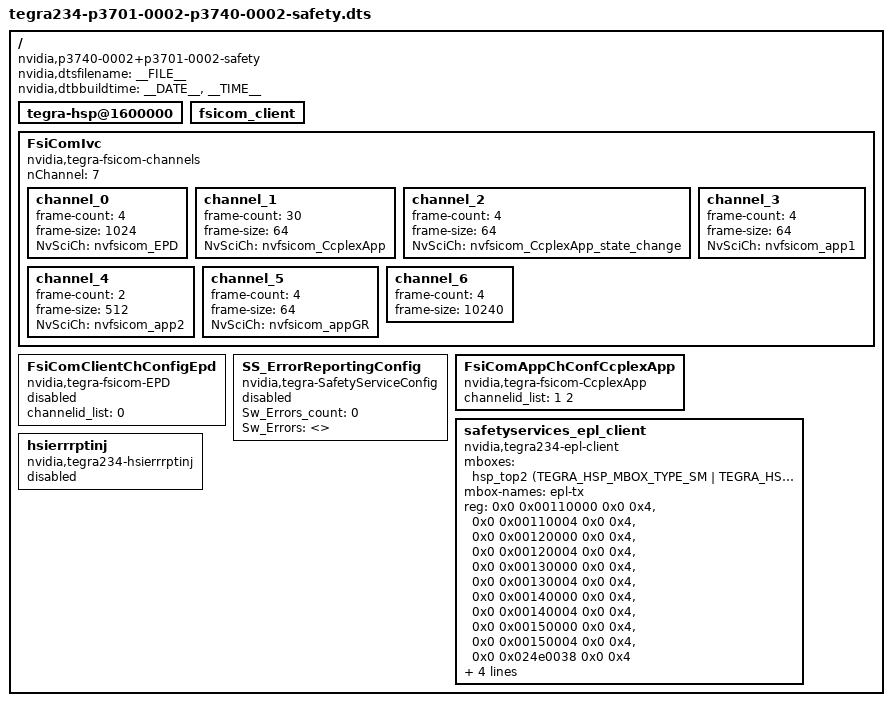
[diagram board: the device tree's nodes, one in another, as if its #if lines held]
/*
 * Top level DTS file for CVM:P3701-0002 and CVB:P3704-0002.
 *
 * Copyright (c) 2022, NVIDIA CORPORATION.  All rights reserved.
 *
 * This program is free software; you can redistribute it and/or modify
 * it under the terms of the GNU General Public License as published by
 * the Free Software Foundation; version 2 of the License.
 *
 * This program is distributed in the hope that it will be useful, but WITHOUT
 * ANY WARRANTY; without even the implied warranty of MERCHANTABILITY or
 * FITNESS FOR A PARTICULAR PURPOSE.  See the GNU General Public License for
 * more details.
 */

/dts-v1/;
#include "tegra234-p3701-0002-p3740-0002.dts"

/ {
	nvidia,dtsfilename = __FILE__;
	nvidia,dtbbuildtime = __DATE__, __TIME__;

	compatible = "nvidia,p3740-0002+p3701-0002-safety", "nvidia,tegra23x",
		      "nvidia,tegra234";

	/* This is hsp_top2 where fsi-ccplex comm happens in all below nodes */
	tegra-hsp@1600000 {
		status = "okay";
	};

	fsicom_client { /* Kernel driver on which FsiComIvc relies on */
		status = "okay";
	};

	FsiComIvc { /* CCPLEX-FSI Comm Daemon uses below DT node */
		compatible = "nvidia,tegra-fsicom-channels";
		status = "okay";
		nChannel=<7>;
		channel_0{
			frame-count = <4>;
			frame-size = <1024>;
			NvSciCh = "nvfsicom_EPD";
		};
		channel_1{
			frame-count = <30>;
			frame-size = <64>;
			NvSciCh = "nvfsicom_CcplexApp";
		};
		channel_2{
			frame-count = <4>;
			frame-size = <64>;
			NvSciCh = "nvfsicom_CcplexApp_state_change";
		};
		channel_3{
			frame-count = <4>;
			frame-size = <64>;
			NvSciCh = "nvfsicom_app1";
		};
		channel_4{
			frame-count = <2>;
			frame-size = <512>;
			NvSciCh = "nvfsicom_app2";
		};
		channel_5{
			frame-count = <4>;
			frame-size = <64>;
			NvSciCh = "nvfsicom_appGR";
		};
		channel_6{
			frame-count = <4>;
			frame-size = <10240>;
		};
	};

	/*
	 * The app is responsible to send runtime tunables from the node SS_ErrorReportingConfig
	 * for the FSI FW
	 */
	FsiComClientChConfigEpd {
                compatible = "nvidia,tegra-fsicom-EPD";
                status = "disabled";
                channelid_list = <0>;
        };

	SS_ErrorReportingConfig {
		compatible = "nvidia,tegra-SafetyServiceConfig";
		status = "disabled";
		/*Number of Sw Errors to be disabled*/
		Sw_Errors_count = <0>;
		/* List of SW errors to disable*/
		/*Entry should be<<reporter id> <mask>>*/
		/* Sample :<0x8000 0xFFFFFFFF>;*/
		/*If the Error code mask is 0xFFFFFFFF then all the error code from the reporter ID will be disabled*/
		Sw_Errors = <>;
	};

	FsiComAppChConfCcplexApp {
		compatible = "nvidia,tegra-fsicom-CcplexApp";
		status = "okay";
		channelid_list = <1 2>;
	};

	safetyservices_epl_client { /* userspace app uses this driver to send error code */
		compatible = "nvidia,tegra234-epl-client";
		/*
		 * FSI FW version 1.1.1 uses HSP 1, while latest FSI FW version
		 * 1.5.4 onwards will be using HSP 0.
		 */
#if TEGRA_HSP_DT_VERSION >= DT_VERSION_2
		mboxes =
			<&hsp_top2 (TEGRA_HSP_MBOX_TYPE_SM | TEGRA_HSP_MBOX_TYPE_SM_128BIT) TEGRA_HSP_SM_TX(0)>;
#else
		mboxes =
			<&hsp_top2 TEGRA_HSP_MBOX_TYPE_SM_128BIT TEGRA_HSP_SM_TX(0)>;
#endif
		mbox-names = "epl-tx";

		reg = <0x0 0x00110000 0x0 0x4>,
			  <0x0 0x00110004 0x0 0x4>,
			  <0x0 0x00120000 0x0 0x4>,
			  <0x0 0x00120004 0x0 0x4>,
			  <0x0 0x00130000 0x0 0x4>,
			  <0x0 0x00130004 0x0 0x4>,
			  <0x0 0x00140000 0x0 0x4>,
			  <0x0 0x00140004 0x0 0x4>,
			  <0x0 0x00150000 0x0 0x4>,
			  <0x0 0x00150004 0x0 0x4>,
			  <0x0 0x024e0038 0x0 0x4>;

		/* Device driver's name for reporting errors via MISCREG_MISC_EC_ERR0_SW_ERR_CODE_0 */
		client-misc-sw-generic-err0 = "fsicom_client";
		/* Device driver's name for reporting errors via MISCREG_MISC_EC_ERR1_SW_ERR_CODE_0 */
		client-misc-sw-generic-err1 = "gk20b";
		/* Device driver's name for reporting errors via MISCREG_MISC_EC_ERR3_SW_ERR_CODE_0 */
		client-misc-sw-generic-err3 = "gk20d";
		/* Device driver's name for reporting errors via MISCREG_MISC_EC_ERR4_SW_ERR_CODE_0 */
		client-misc-sw-generic-err4 = "gk20e";

		status = "okay";
	};

	/*
	 * FIXME: there is no auto dtsi which enables this driver, and its mailbox
	 * shown in its yaml file overlaps with the fsicom_client driver. Keeping
	 * this disabled till it gets sorted out.
	 */
	hsierrrptinj {
		compatible = "nvidia,tegra234-hsierrrptinj";
		status = "disabled";
	};
};
